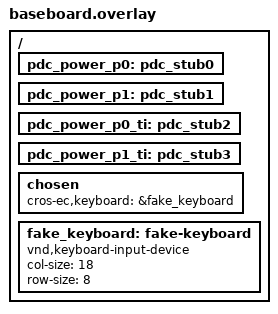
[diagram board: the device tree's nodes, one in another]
/* Copyright 2024 The ChromiumOS Authors
 * Use of this source code is governed by a BSD-style license that can be
 * found in the LICENSE file.
 */

#include <dt-bindings/kbd.h>
#include <it8xxx2_emul.dts>

#include "baseboard.dtsi"

/{
	/* Stub PDC nodes. Only needed for the node label. Don't actually
	 * instantiate any PDC drivers for simplicity.
	 */
	pdc_power_p0: pdc_stub0 {
	};
	pdc_power_p1: pdc_stub1 {
	};
	pdc_power_p0_ti: pdc_stub2 {
	};
	pdc_power_p1_ti: pdc_stub3 {
	};

	chosen {
		cros-ec,keyboard = &fake_keyboard;
	};

	fake_keyboard: fake-keyboard {
		compatible = "vnd,keyboard-input-device";
		col-size = <18>;
		row-size = <8>;
	};
};
